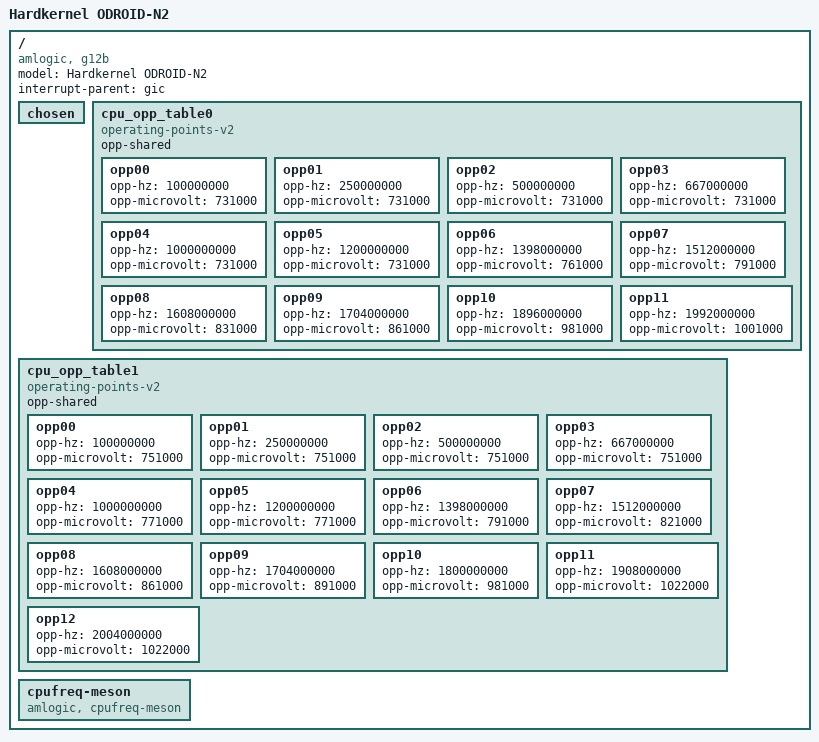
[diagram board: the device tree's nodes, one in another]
/*
 * arch/arm64/boot/dts/amlogic/meson64_odroidn2.dts
 *
 * Copyright (C) 2018 Hardkernel Co,. Ltd. All rights reserved.
 *
 * This program is free software; you can redistribute it and/or modify
 * it under the terms of the GNU General Public License as published by
 * the Free Software Foundation; either version 2 of the License, or
 * (at your option) any later version.
 *
 * This program is distributed in the hope that it will be useful, but WITHOUT
 * ANY WARRANTY; without even the implied warranty of MERCHANTABILITY or
 * FITNESS FOR A PARTICULAR PURPOSE.  See the GNU General Public License for
 * more details.
 *
 */

/dts-v1/;

#include "mesong12b_a.dtsi"
#include "meson64_odroidn2.dtsi"

/ {
	model = "Hardkernel ODROID-N2";
	compatible = "amlogic, g12b";
	interrupt-parent = <&gic>;
	#address-cells = <2>;
	#size-cells = <2>;

	chosen { };

	cpu_opp_table0: cpu_opp_table0 {
		compatible = "operating-points-v2";
		opp-shared;

		opp00 {
			opp-hz = /bits/ 64 <100000000>;
			opp-microvolt = <731000>;
		};
		opp01 {
			opp-hz = /bits/ 64 <250000000>;
			opp-microvolt = <731000>;
		};
		opp02 {
			opp-hz = /bits/ 64 <500000000>;
			opp-microvolt = <731000>;
		};
		opp03 {
			opp-hz = /bits/ 64 <667000000>;
			opp-microvolt = <731000>;
		};
		opp04 {
			opp-hz = /bits/ 64 <1000000000>;
			opp-microvolt = <731000>;
		};
		opp05 {
			opp-hz = /bits/ 64 <1200000000>;
			opp-microvolt = <731000>;
		};
		opp06 {
			opp-hz = /bits/ 64 <1398000000>;
			opp-microvolt = <761000>;
		};
		opp07 {
			opp-hz = /bits/ 64 <1512000000>;
			opp-microvolt = <791000>;
		};
		opp08 {
			opp-hz = /bits/ 64 <1608000000>;
			opp-microvolt = <831000>;
		};
		opp09 {
			opp-hz = /bits/ 64 <1704000000>;
			opp-microvolt = <861000>;
		};
		opp10 {
			opp-hz = /bits/ 64 <1896000000>;
			opp-microvolt = <981000>;
		};
		opp11 {
			opp-hz = /bits/ 64 <1992000000>;
			opp-microvolt = <1001000>;
		};
	};

	cpu_opp_table1: cpu_opp_table1 {
		compatible = "operating-points-v2";
		opp-shared;

		opp00 {
			opp-hz = /bits/ 64 <100000000>;
			opp-microvolt = <751000>;
		};
		opp01 {
			opp-hz = /bits/ 64 <250000000>;
			opp-microvolt = <751000>;
		};
		opp02 {
			opp-hz = /bits/ 64 <500000000>;
			opp-microvolt = <751000>;
		};
		opp03 {
			opp-hz = /bits/ 64 <667000000>;
			opp-microvolt = <751000>;
		};
		opp04 {
			opp-hz = /bits/ 64 <1000000000>;
			opp-microvolt = <771000>;
		};
		opp05 {
			opp-hz = /bits/ 64 <1200000000>;
			opp-microvolt = <771000>;
		};
		opp06 {
			opp-hz = /bits/ 64 <1398000000>;
			opp-microvolt = <791000>;
		};
		opp07 {
			opp-hz = /bits/ 64 <1512000000>;
			opp-microvolt = <821000>;
		};
		opp08 {
			opp-hz = /bits/ 64 <1608000000>;
			opp-microvolt = <861000>;
		};
		opp09 {
			opp-hz = /bits/ 64 <1704000000>;
			opp-microvolt = <891000>;
		};
		opp10 {
			opp-hz = /bits/ 64 <1800000000>;
			opp-microvolt = <981000>;
		};
		opp11 {
			opp-hz = /bits/ 64 <1908000000>;
			opp-microvolt = <1022000>;
		};
		opp12 {
			opp-hz = /bits/ 64 <2004000000>;
			opp-microvolt = <1022000>;
		};
	};

	cpufreq-meson {
		compatible = "amlogic, cpufreq-meson";
		status = "okay";
	};
}; /* end of / */
